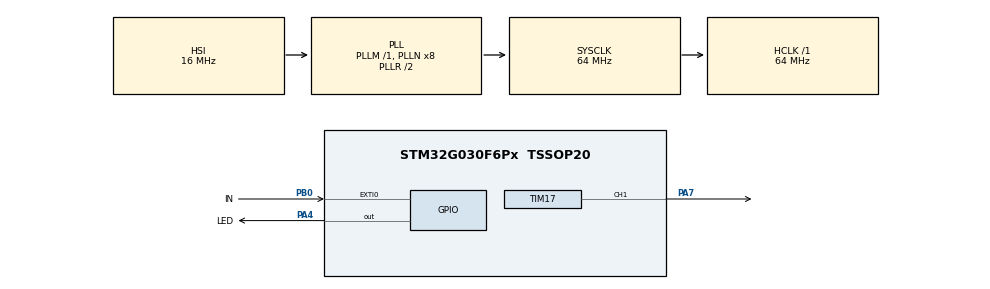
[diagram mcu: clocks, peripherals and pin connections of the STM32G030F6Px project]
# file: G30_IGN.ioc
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Mcu.Family=STM32G0
Mcu.Name=STM32G030F6Px
Mcu.Package=TSSOP20
NVIC.EXTI0_1_IRQn=true\:0\:0\:false\:false\:true\:true\:true\:true
NVIC.TIM16_IRQn=true\:0\:0\:false\:false\:true\:true\:true\:true
PA13.Mode=Serial_Wire
PA13.Signal=SYS_SWDIO
PA14-BOOT0.Mode=Serial_Wire
PA14-BOOT0.Signal=SYS_SWCLK
PA14-BOOT0__PA15.StandardMode=true
PA4.GPIO_Label=LED
PA4.GPIO_PuPd=GPIO_PULLDOWN
PA4.Signal=GPIO_Output
PA7.Signal=S_TIM17_CH1
PB0.GPIO_Label=IN
PB0.GPIO_ModeDefaultEXTI=GPIO_MODE_IT_RISING_FALLING
PB0.GPIO_PuPd=GPIO_PULLDOWN
PB0.Signal=GPXTI0
PB0__PB1__PB2__PA8.StandardMode=true
PB3__PB4__PB5__PB6.StandardMode=true
PB7__PB8.StandardMode=true
PC14-OSC32_IN\ (PC14)__PB9.StandardMode=true
ProjectManager.HeapSize=0x200
ProjectManager.StackSize=0x400
ProjectManager.TargetToolchain=STM32CubeIDE
RCC.ADCFreq_Value=64000000
RCC.AHBFreq_Value=64000000
RCC.CortexFreq_Value=64000000
RCC.EXTERNAL_CLOCK_VALUE=12288000
RCC.HCLKFreq_Value=64000000
RCC.HSE_VALUE=8000000
RCC.HSI_VALUE=16000000
RCC.LSE_VALUE=32768
RCC.SYSCLKFreq_VALUE=64000000
RCC.SYSCLKSource=RCC_SYSCLKSOURCE_PLLCLK
RCC.VCOOutputFreq_Value=128000000
SH.S_TIM17_CH1.0=TIM17_CH1,PWM Generation1 CH1
TIM16.Period=63999
TIM16.Prescaler=999
TIM17.Channel=TIM_CHANNEL_1
TIM17.OCFastMode_PWM=TIM_OCFAST_ENABLE
TIM17.OCMode_PWM=TIM_OCMODE_PWM2
TIM17.Period=63999
TIM17.Prescaler=999
TIM17.Pulse=128
VP_TIM16_VS_ClockSourceINT.Mode=Enable_Timer
VP_TIM17_VS_ClockSourceINT.Mode=Enable_Timer
VP_TIM17_VS_OPM.Mode=OPM_bit
board=custom

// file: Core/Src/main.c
/* USER CODE BEGIN Header */
/**
  ******************************************************************************
  * @file           : main.c
  * @brief          : Main program body
  ******************************************************************************
  * @attention
  *
  * Copyright (c) 2024 STMicroelectronics.
  * All rights reserved.
  *
  * This software is licensed under terms that can be found in the LICENSE file
  * in the root directory of this software component.
  * If no LICENSE file comes with this software, it is provided AS-IS.
  *
  ******************************************************************************
  */
/* USER CODE END Header */
#include "main.h"
#include "tim.h"
#include "gpio.h"

/* USER CODE BEGIN Includes */
#include "ignition.h"
/* USER CODE END Includes */

/* USER CODE BEGIN PD */
uint8_t early_ignition = 1;
int timer_temp_rpm = 0, rpm =0, calculated_delay= 130;
/* USER CODE END PD */

void SystemClock_Config(void);

int main(void)
{

  /* MCU Configuration--------------------------------------------------------*/

  /* Reset of all peripherals, Initializes the Flash interface and the Systick. */
  HAL_Init();

  /* Configure the system clock */
  SystemClock_Config();

  /* Initialize all configured peripherals */
  MX_GPIO_Init();
  MX_TIM17_Init();
  MX_TIM16_Init();

  /* Infinite loop */
  while (1)
  {
	  if (early_ignition == 1){
		  rpm = rpm_conversion(timer_temp_rpm);
		  calculated_delay= set_delay_by(rpm);
	  } else {
		  calculated_delay = 130;
	  }
  }
}

void SystemClock_Config(void)
{
  RCC_OscInitTypeDef RCC_OscInitStruct = {0};
  RCC_ClkInitTypeDef RCC_ClkInitStruct = {0};

  /** Configure the main internal regulator output voltage
  */
  HAL_PWREx_ControlVoltageScaling(PWR_REGULATOR_VOLTAGE_SCALE1);

  /** Initializes the RCC Oscillators according to the specified parameters
  * in the RCC_OscInitTypeDef structure.
  */
  RCC_OscInitStruct.OscillatorType = RCC_OSCILLATORTYPE_HSI;
  RCC_OscInitStruct.HSIState = RCC_HSI_ON;
  RCC_OscInitStruct.HSIDiv = RCC_HSI_DIV1;
  RCC_OscInitStruct.HSICalibrationValue = RCC_HSICALIBRATION_DEFAULT;
  RCC_OscInitStruct.PLL.PLLState = RCC_PLL_ON;
  RCC_OscInitStruct.PLL.PLLSource = RCC_PLLSOURCE_HSI;
  RCC_OscInitStruct.PLL.PLLM = RCC_PLLM_DIV1;
  RCC_OscInitStruct.PLL.PLLN = 8;
  RCC_OscInitStruct.PLL.PLLP = RCC_PLLP_DIV2;
  RCC_OscInitStruct.PLL.PLLR = RCC_PLLR_DIV2;
  if (HAL_RCC_OscConfig(&RCC_OscInitStruct) != HAL_OK)
  {
    Error_Handler();
  }

  /** Initializes the CPU, AHB and APB buses clocks
  */
  RCC_ClkInitStruct.ClockType = RCC_CLOCKTYPE_HCLK|RCC_CLOCKTYPE_SYSCLK
                              |RCC_CLOCKTYPE_PCLK1;
  RCC_ClkInitStruct.SYSCLKSource = RCC_SYSCLKSOURCE_PLLCLK;
  RCC_ClkInitStruct.AHBCLKDivider = RCC_SYSCLK_DIV1;
  RCC_ClkInitStruct.APB1CLKDivider = RCC_HCLK_DIV1;

  if (HAL_RCC_ClockConfig(&RCC_ClkInitStruct, FLASH_LATENCY_2) != HAL_OK)
  {
    Error_Handler();
  }
}

/* USER CODE BEGIN 4 */
void HAL_GPIO_EXTI_Rising_Callback(uint16_t GPIO_Pin){
		HAL_TIM_Base_Stop_IT(&htim16);
		__HAL_TIM_CLEAR_FLAG(&htim16, TIM_SR_UIF);
		TIM16->ARR= 0;
		HAL_TIM_Base_Start_IT(&htim16);
}

void HAL_GPIO_EXTI_Falling_Callback(uint16_t GPIO_Pin){

		TIM17->ARR = calculated_delay;
		__HAL_TIM_CLEAR_FLAG(&htim17, TIM_SR_UIF);
		HAL_TIM_PWM_Start_IT(&htim17, TIM_CHANNEL_1);

	HAL_TIM_Base_Stop_IT(&htim16);
	timer_temp_rpm = TIM16->ARR;
}

void HAL_TIM_PeriodElapsedCallback(TIM_HandleTypeDef *htim)
{
        if(htim->Instance == TIM16)
        { //Если мы тут- значит двигатель заводится через пизду, ставим сток.
        	HAL_TIM_Base_Stop_IT(&htim16);
        	TIM16->ARR= 0;
        	early_ignition = 1;
        }
}
void HAL_TIM_PWM_PulseFinishedCallback(TIM_HandleTypeDef *htim){
	if(htim->Instance == TIM17)
	        {
	        	HAL_TIM_PWM_Stop_IT(&htim17, TIM_CHANNEL_1);

	        }

}

/* USER CODE END 4 */

void Error_Handler(void)
{
  __disable_irq();
  while (1)
  {
  }
}
